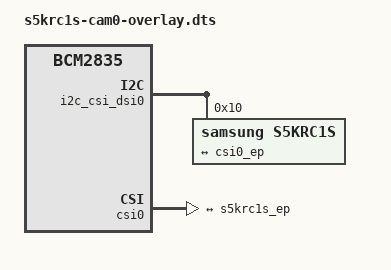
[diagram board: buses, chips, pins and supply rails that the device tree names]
/dts-v1/;
/plugin/;

/ {
	compatible = "brcm,bcm2835";

	fragment@0 {
		target = <&i2c_csi_dsi0>;
		__overlay__ {
			#address-cells = <1>;
			#size-cells = <0>;
			status = "okay";

			s5krc1s: s5krc1s@10 {
				compatible = "samsung,s5krc1s";
				reg = <0x10>;
				status = "okay";

				port {
					s5krc1s_ep: endpoint {
						remote-endpoint = <&csi0_ep>;
						clock-lanes = <0>;
						data-lanes = <1 2 3 4>;
						link-frequencies = /bits/ 64 <400000000>;
					};
				};
			};
		};
	};

	fragment@1 {
		target = <&csi0>;
		__overlay__ {
			status = "okay";

			port {
				csi0_ep: endpoint {
					remote-endpoint = <&s5krc1s_ep>;
					clock-lanes = <0>;
					data-lanes = <1 2 3 4>;
				};
			};
		};
	};

	__overrides__ {
		2lane = <&s5krc1s_ep>,"data-lanes:0=", <1 2>,
			<&csi0_ep>,"data-lanes:0=", <1 2>;
	};
};
